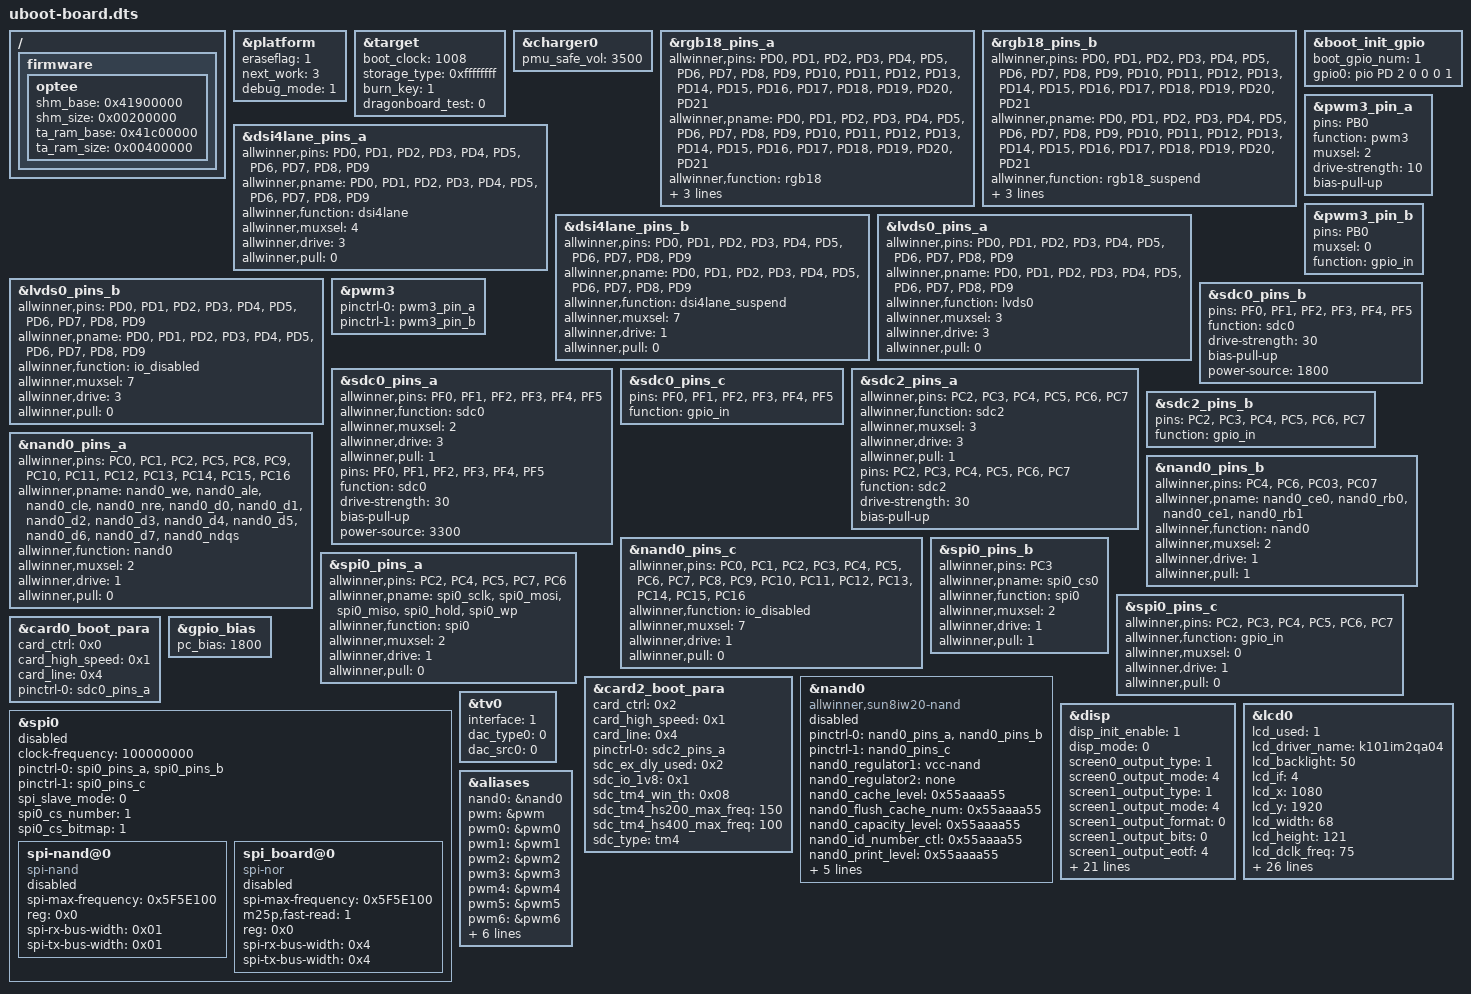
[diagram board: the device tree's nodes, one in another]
/*
 * Allwinner Technology CO., Ltd. sun8iw20p1 soc board.
 *
 * soc board support.
 */
//  #include "ebyte-t113-mipi.dtsi"
/{
	firmware {
		optee {
			shm_base = <0x41900000>;
			shm_size = <0x00200000>;
			ta_ram_base = <0x41c00000>;
			ta_ram_size = <0x00400000>;
		};
	};
};

&platform {
	eraseflag   = <1>;
	next_work   = <3>;
	debug_mode  = <1>;
};

&target {
	boot_clock = <1008>;	/*CPU boot frequency, Unit: MHz*/
	storage_type = <0xffffffff>; /*boot medium, 0-nand, 1-card0, 2-card2, -1(defualt)auto scan*/
	burn_key = <1>;		/*1:support burn key; 0:not support burn key*/
	dragonboard_test = <0>;	/*1:support card boot dragonboard; 0:not support card boot dragonboard*/
};


&charger0 {
	pmu_safe_vol = <3500>;
};

&rgb18_pins_a {
	allwinner,pins = "PD0", "PD1", "PD2", "PD3", "PD4", "PD5", "PD6", "PD7", "PD8", "PD9", \
	"PD10", "PD11", "PD12", "PD13", "PD14", "PD15", "PD16", "PD17", "PD18", "PD19", \
	"PD20", "PD21";
	allwinner,pname = "PD0", "PD1", "PD2", "PD3", "PD4", "PD5", "PD6", "PD7", "PD8", "PD9", \
	"PD10", "PD11", "PD12", "PD13", "PD14", "PD15", "PD16", "PD17", "PD18", "PD19", \
	"PD20", "PD21";
	allwinner,function = "rgb18";
	allwinner,muxsel = <2>;
	allwinner,drive = <3>;
	allwinner,pull = <0>;
};

&rgb18_pins_b {
	allwinner,pins = "PD0", "PD1", "PD2", "PD3", "PD4", "PD5", "PD6", "PD7", "PD8", "PD9", \
	"PD10", "PD11", "PD12", "PD13", "PD14", "PD15", "PD16", "PD17", "PD18", "PD19", \
	"PD20", "PD21";
	allwinner,pname = "PD0", "PD1", "PD2", "PD3", "PD4", "PD5", "PD6", "PD7", "PD8", "PD9", \
	"PD10", "PD11", "PD12", "PD13", "PD14", "PD15", "PD16", "PD17", "PD18", "PD19", \
	"PD20", "PD21";
	allwinner,function = "rgb18_suspend";
	allwinner,muxsel = <7>;
	allwinner,drive = <1>;
	allwinner,pull = <0>;
};

&dsi4lane_pins_a {
    allwinner,pins = "PD0", "PD1", "PD2", "PD3", "PD4", "PD5", "PD6", "PD7", "PD8", "PD9";
    allwinner,pname = "PD0", "PD1", "PD2", "PD3", "PD4", "PD5", "PD6", "PD7", "PD8", "PD9";
    allwinner,function = "dsi4lane";
    allwinner,muxsel = <4>;
    allwinner,drive = <3>;
    allwinner,pull = <0>;
	};

&dsi4lane_pins_b {
    allwinner,pins = "PD0", "PD1", "PD2", "PD3", "PD4", "PD5", "PD6", "PD7", "PD8", "PD9";
    allwinner,pname = "PD0", "PD1", "PD2", "PD3", "PD4", "PD5", "PD6", "PD7", "PD8", "PD9";
    allwinner,function = "dsi4lane_suspend";
    allwinner,muxsel = <7>;
    allwinner,drive = <1>;
    allwinner,pull = <0>;
};

&lvds0_pins_a {
	allwinner,pins  = "PD0", "PD1", "PD2", "PD3", "PD4", "PD5", "PD6", "PD7", "PD8", "PD9";
	allwinner,pname = "PD0", "PD1", "PD2", "PD3", "PD4", "PD5", "PD6", "PD7", "PD8", "PD9";
	allwinner,function = "lvds0";
	allwinner,muxsel = <3>;
	allwinner,drive = <3>;
	allwinner,pull = <0>;
};

&lvds0_pins_b {
	allwinner,pins  = "PD0", "PD1", "PD2", "PD3", "PD4", "PD5", "PD6", "PD7", "PD8", "PD9";
	allwinner,pname = "PD0", "PD1", "PD2", "PD3", "PD4", "PD5", "PD6", "PD7", "PD8", "PD9";
	allwinner,function = "io_disabled";
	allwinner,muxsel = <7>;
	allwinner,drive = <3>;
	allwinner,pull = <0>;
};


&boot_init_gpio{
	boot_gpio_num=<1>;
	gpio0        = <&pio PD 2 0 0 0 1>;
    status = "okay";
};


&pwm3_pin_a {
	pins = "PB0";
	function = "pwm3";
	muxsel = <2>;
	drive-strength = <10>;
	bias-pull-up;
};

&pwm3_pin_b {
	pins = "PB0";
	muxsel = <0>;
	function = "gpio_in";
};

&pwm3 {
	pinctrl-names = "active", "sleep";
	pinctrl-0 = <&pwm3_pin_a>;
	pinctrl-1 = <&pwm3_pin_b>;
	status = "okay";
};

&sdc0_pins_a {
	allwinner,pins = "PF0", "PF1", "PF2",
			 "PF3", "PF4", "PF5";
	allwinner,function = "sdc0";
	allwinner,muxsel = <2>;
	allwinner,drive = <3>;
	allwinner,pull = <1>;
	pins = "PF0", "PF1", "PF2",
	       "PF3", "PF4", "PF5";
	function = "sdc0";
	drive-strength = <30>;
	bias-pull-up;
	power-source = <3300>;
};

&sdc0_pins_b {
	pins = "PF0", "PF1", "PF2",
	       "PF3", "PF4", "PF5";
	function = "sdc0";
	drive-strength = <30>;
	bias-pull-up;
	power-source = <1800>;
};

&sdc0_pins_c {
		pins = "PF0", "PF1", "PF2",
			"PF3", "PF4", "PF5";
		function = "gpio_in";

};


&sdc2_pins_a {
	allwinner,pins = "PC2", "PC3", "PC4",
			 "PC5", "PC6", "PC7";
	allwinner,function = "sdc2";
	allwinner,muxsel = <3>;
	allwinner,drive = <3>;
	allwinner,pull = <1>;
	pins = "PC2", "PC3", "PC4",
		"PC5", "PC6", "PC7";
	function = "sdc2";
	drive-strength = <30>;
	bias-pull-up;

};

&sdc2_pins_b {
	pins = "PC2", "PC3", "PC4",
	       "PC5", "PC6", "PC7";
	function = "gpio_in";
};



&nand0_pins_a {
	allwinner,pins = "PC0", "PC1", "PC2", "PC5",
			 "PC8", "PC9", "PC10", "PC11",
			 "PC12", "PC13", "PC14", "PC15",
			 "PC16";
	allwinner,pname= "nand0_we", "nand0_ale","nand0_cle", "nand0_nre",
			 "nand0_d0", "nand0_d1", "nand0_d2", "nand0_d3",
			 "nand0_d4", "nand0_d5", "nand0_d6", "nand0_d7",
			 "nand0_ndqs";
	allwinner,function = "nand0";
	allwinner,muxsel = <2>;
	allwinner,drive = <1>;
	allwinner,pull = <0>;
};

&nand0_pins_b {
	allwinner,pins = "PC4", "PC6", "PC03", "PC07";
	allwinner,pname= "nand0_ce0", "nand0_rb0", "nand0_ce1", "nand0_rb1";
	allwinner,function = "nand0";
	allwinner,muxsel = <2>;
	allwinner,drive = <1>;
	allwinner,pull = <1>;	/* only RB&CE should be pulled up */
};

&nand0_pins_c {
	allwinner,pins = "PC0", "PC1", "PC2", "PC3",
			 "PC4", "PC5", "PC6", "PC7",
			 "PC8", "PC9", "PC10", "PC11",
			 "PC12", "PC13", "PC14", "PC15",
			 "PC16";
	allwinner,function = "io_disabled";
	allwinner,muxsel = <7>;
	allwinner,drive = <1>;
	allwinner,pull = <0>;
};

&spi0_pins_a {
	allwinner,pins = "PC2", "PC4", "PC5",
			"PC7", "PC6";
	allwinner,pname = "spi0_sclk", "spi0_mosi",
			"spi0_miso", "spi0_hold", "spi0_wp";
	allwinner,function = "spi0";
	allwinner,muxsel = <2>;
	allwinner,drive = <1>;
	allwinner,pull = <0>;
};

&spi0_pins_b {
	allwinner,pins = "PC3";
	allwinner,pname = "spi0_cs0";
	allwinner,function = "spi0";
	allwinner,muxsel = <2>;
	allwinner,drive = <1>;
	allwinner,pull = <1>;   // only CS should be pulled up
};

&spi0_pins_c {
	allwinner,pins = "PC2", "PC3", "PC4", "PC5",
			"PC6", "PC7";
	allwinner,function = "gpio_in";
	allwinner,muxsel = <0>;
	allwinner,drive = <1>;
	allwinner,pull = <0>;
};

&card0_boot_para {  /* Avoid dtc compiling warnings. @TODO: Developer should modify this to the actual value */
	/* reg = <0x0 0x2 0x0 0x0>;  [> Avoid dtc compiling warnings. @TODO: Developer should modify this to the actual value <] */
	device_type = "card0_boot_para";
	card_ctrl = <0x0>;
	card_high_speed = <0x1>;
	card_line = <0x4>;
	pinctrl-0 = <&sdc0_pins_a>;
};

&card2_boot_para {  /* Avoid dtc compiling warnings. @TODO: Developer should modify this to the actual value */
	/* reg = <0x0 0x3 0x0 0x0>;  [> Avoid dtc compiling warnings. @TODO: Developer should modify this to the actual value <] */
	device_type = "card2_boot_para";
	card_ctrl = <0x2>;
	card_high_speed = <0x1>;
	card_line = <0x4>;
	pinctrl-0 = <&sdc2_pins_a>;
	sdc_ex_dly_used = <0x2>;
	sdc_io_1v8 = <0x1>;
	sdc_tm4_win_th = <0x08>;
	sdc_tm4_hs200_max_freq = <150>;
	sdc_tm4_hs400_max_freq = <100>;
	sdc_type = "tm4";
};
&gpio_bias {  /* Avoid dtc compiling warnings. @TODO: Developer should modify this to the actual value */
	device_type = "gpio_bias";
	pc_bias = <1800>;
};

&nand0 {
	compatible = "allwinner,sun8iw20-nand";
	device_type = "nand0";
	//reg = <0x0 0x04011000 0x0 0x1000>;/* nand0 */
	pinctrl-names = "default", "sleep";
	pinctrl-0 = <&nand0_pins_a &nand0_pins_b>;
	pinctrl-1 = <&nand0_pins_c>;
	nand0_regulator1 = "vcc-nand";
	nand0_regulator2 = "none";
	nand0_cache_level = <0x55aaaa55>;
	nand0_flush_cache_num = <0x55aaaa55>;
	nand0_capacity_level = <0x55aaaa55>;
	nand0_id_number_ctl = <0x55aaaa55>;
	nand0_print_level = <0x55aaaa55>;
	nand0_p0 = <0x55aaaa55>;
	nand0_p1 = <0x55aaaa55>;
	nand0_p2 = <0x55aaaa55>;
	nand0_p3 = <0x55aaaa55>;
	chip_code = "sun8iw20";
	status = "disabled";
};

&spi0 {
	clock-frequency = <100000000>;
	pinctrl-0 = <&spi0_pins_a &spi0_pins_b>;
	pinctrl-1 = <&spi0_pins_c>;
	pinctrl-names = "default", "sleep";
	/*spi-supply = <&reg_dcdc1>;*/
	spi_slave_mode = <0>;
	spi0_cs_number = <1>;
	spi0_cs_bitmap = <1>;
	status = "disabled";

	spi-nand@0 {
		compatible = "spi-nand";
		spi-max-frequency=<0x5F5E100>;
		reg = <0x0>;
		spi-rx-bus-width=<0x01>;
		spi-tx-bus-width=<0x01>;
		status="disabled";
	};

	spi_board@0 {
		device_type = "spi_board0";
		compatible = "spi-nor";
		spi-max-frequency = <0x5F5E100>;
		m25p,fast-read = <1>;
		reg = <0x0>;
		spi-rx-bus-width = <0x4>;
		spi-tx-bus-width = <0x4>;
		status = "disabled";
	};
};

/*----------------------------------------------------------------------------------
disp init configuration

disp_mode             (0:screen0<screen0,fb0>)
screenx_output_type   (0:none; 1:lcd; 2:tv; 5:vdpo)
fbx format            (4:RGB655 5:RGB565 6:RGB556 7:ARGB1555 8:RGBA5551 9:RGB888 10:ARGB8888 12:ARGB4444)
fbx pixel sequence    (0:ARGB 1:BGRA 2:ABGR 3:RGBA)
fb0_scaler_mode_enable(scaler mode enable, used FE)
fbx_width,fbx_height  (framebuffer horizontal/vertical pixels, fix to output resolution while equal 0)
lcdx_backlight        (lcd init backlight,the range:[0,256],default:197
lcdx_yy               (lcd init screen bright/contrast/saturation/hue, value:0~100, default:50/50/57/50)
lcd0_contrast         (LCD contrast, 0~100)
lcd0_saturation       (LCD saturation, 0~100)
lcd0_hue              (LCD hue, 0~100)
framebuffer software rotation setting:
disp_rotation_used:   (0:disable; 1:enable,you must set fbX_width to lcd_y,
set fbX_height to lcd_x)
degreeX:              (X:screen index; 0:0 degree; 1:90 degree; 3:270 degree)
degreeX_Y:            (X:screen index; Y:layer index 0~15; 0:0 degree; 1:90 degree; 3:270 degree)
devX_output_type : config output type in bootGUI framework in UBOOT-2018.
				   (0:none; 1:lcd; 2:tv;)
devX_output_mode : config output resolution(see include/video/sunxi_display2.h) of bootGUI framework in UBOOT-2018
devX_screen_id   : config display index of bootGUI framework in UBOOT-2018
devX_do_hpd      : whether do hpd detectation or not in UBOOT-2018
chn_cfg_mode     : Hardware DE channel allocation config. 0:single display with 6
				   channel, 1:dual display with 4 channel in main display and 2 channel in second
                   display, 2:dual display with 3 channel in main display and 3 channel in second
                   in display.
----------------------------------------------------------------------------------*/
&disp {
	disp_init_enable         = <1>;
	disp_mode                = <0>;

	/*lcd*/
	screen0_output_type      = <1>;
	screen0_output_mode      = <4>;

	/*cbvs*/
	// screen0_output_type      = <2>;
	// screen0_output_mode      = <14>;


	screen1_output_type      = <1>;
	screen1_output_mode      = <4>;

	screen1_output_format    = <0>;
	screen1_output_bits      = <0>;
	screen1_output_eotf      = <4>;
	screen1_output_cs        = <257>;
	screen1_output_range     = <2>;
	screen1_output_scan      = <0>;
	screen1_output_aspect_ratio = <8>;

	/*lcd*/
	dev0_output_type         = <1>;
	dev0_output_mode         = <4>;
	dev0_screen_id           = <0>;
	dev0_do_hpd              = <0>;
	/*cbvs*/
	// dev0_output_type         = <2>;
	// dev0_output_mode         = <14>;
	// dev0_screen_id           = <0>;
	// dev0_do_hpd              = <1>;

	dev1_output_type         = <4>;
	dev1_output_mode         = <10>;
	dev1_screen_id           = <1>;
	dev1_do_hpd              = <1>;
	/*cvbs*/
	// dev1_output_type         = <1>;
	// dev1_output_mode         = <4>;
	// dev1_screen_id           = <1>;
	// dev1_do_hpd              = <1>;


	def_output_dev           = <0>;

	/*lcd*/
	fb0_format               = <0>;
	fb0_width                = <1080>;
	fb0_height               = <1920>;
	/*cvbs*/
	// fb0_format               = <0>;
	// fb0_width                = <720>;
	// fb0_height               = <480>;

	/*lcd*/
	fb1_format               = <0>;
	fb1_width                = <0>;
	fb1_height               = <0>;
	chn_cfg_mode             = <1>;
	/*cvbs*/
	// fb1_format               = <0>;
	// fb1_width                = <1920>;
	// fb1_height               = <1080>;
	// chn_cfg_mode             = <1>;

	disp_para_zone           = <1>;
	/*VCC-LCD*/
/*	dc1sw-supply = <&reg_dc1sw>;*/
	/*VCC-DSI*/
/*	eldo3-supply = <&reg_eldo3>;*/
	/*VCC-PD*/
/*	dcdc1-supply = <&reg_dcdc1>;*/
};
/*----------------------------------------------------------------------------------
;lcd0 configuration

;lcd_if:               0:hv(sync+de); 1:8080; 2:ttl; 3:lvds; 4:dsi; 5:edp; 6:extend dsi
;lcd_hv_if             0:Parallel RGB; 8:Serial RGB; 10:Dummy RGB; 11: RGB Dummy;12:CCIR656
;lcd_hv_clk_phase      0:0 degree;1:90 degree;2:180 degree;3:270 degree
;lcd_hv_sync_polarity  0:vs low,hs low; 1:vs high,hslow; 2:vs low,hs high; 3:vs high,hs high
;lcd_hv_syuv_seq       0:YUYV; 1:YVYU; 2:UYVY; 3:VYUY
;lcd_cpu_if            0:18bit/1 cycle parallel(RGB666); 4:16bit/1cycle parallel (RGB565)
;                      6:18bit/3 cycle parallel(RGB666); 7:16bit/2cycle parallel (RGB565)
;lcd_cpu_te            0:frame auto trigger; 1:frame triggered by te rising edge; 2:frame triggered by te falling edge;
;lcd_dsi_if            0:video mode; 1: Command mode; 2:video burst mode
;lcd_dsi_te            0:frame auto trigger; 1:frame triggered by te rising edge; 2:frame triggered by te falling edge;
;lcd_x:                lcd horizontal resolution
;lcd_y:                lcd vertical resolution
;lcd_width:            width of lcd in mm
;lcd_height:           height of lcd in mm
;lcd_dclk_freq:        in MHZ unit
;lcd_pwm_freq:         in HZ unit
;lcd_pwm_pol:          lcd backlight PWM polarity
;lcd_pwm_max_limit     lcd backlight PWM max limit(<=255)
;lcd_hbp:              hsync back porch(pixel) + hsync plus width(pixel);
;lcd_ht:               hsync total cycle(pixel)
;lcd_vbp:              vsync back porch(line) + vysnc plus width(line)
;lcd_vt:               vysnc total cycle(line)
;lcd_hspw:             hsync plus width(pixel)
;lcd_vspw:             vysnc plus width(pixel)
;lcd_lvds_if:          0:single link;  1:dual link
;lcd_lvds_colordepth:  0:8bit; 1:6bit
;lcd_lvds_mode:        0:NS mode; 1:JEIDA mode
;lcd_frm:              0:disable; 1:enable rgb666 dither; 2:enable rgb656 dither
;lcd_io_phase:         0:noraml; 1:intert phase(0~3bit: vsync phase; 4~7bit:hsync phase;
;                      8~11bit:dclk phase; 12~15bit:de phase)
;lcd_gamma_en          lcd gamma correction enable
;lcd_bright_curve_en   lcd bright curve correction enable
;lcd_cmap_en           lcd color map function enable
;deu_mode              0:smoll lcd screen; 1:large lcd screen(larger than 10inch)
;lcdgamma4iep:         Smart Backlight parameter, lcd gamma vale * 10;
;                      decrease it while lcd is not bright enough; increase while lcd is too bright
;smart_color           90:normal lcd screen 65:retina lcd screen(9.7inch)
;Pin setting for special function ie.LVDS, RGB data or vsync
;   name(donot care) = port:PD12<pin function><pull up or pull down><drive ability><output level>
;Pin setting for gpio:
;   lcd_gpio_X     = port:PD12<pin function><pull up or pull down><drive ability><output level>
;Pin setting for backlight enable pin
;   lcd_bl_en     = port:PD12<pin function><pull up or pull down><drive ability><output level>
;fsync setting, pulse to csi
;lcd_fsync_en          (0:disable fsync,1:enable)
;lcd_fsync_act_time    (active time of fsync, unit:pixel)
;lcd_fsync_dis_time    (disactive time of fsync, unit:pixel)
;lcd_fsync_pol         (0:positive;1:negative)
;gpio config: <&pio for cpu or &r_pio for cpus, port, port num, pio function,
pull up or pull down(default 0), driver level(default 1), data>
;For dual link lvds: use lvds2link_pins_a  and lvds2link_pins_b instead
;For rgb24: use rgb24_pins_a  and rgb24_pins_b instead
;For lvds1: use lvds1_pins_a  and lvds1_pins_b instead
;For lvds0: use lvds0_pins_a  and lvds0_pins_b instead
;----------------------------------------------------------------------------------*/
// panel-lt8912b-hdmi  k101im2qa04 he0801a068 jd9366ab_3 jd9161z
&lcd0 {
	lcd_used            = <1>;
	lcd_driver_name     = "k101im2qa04";
    lcd_backlight       = <50>;

	lcd_if              = <4>;

	lcd_x               = <1080>;
	lcd_y               = <1920>;
	lcd_width           = <68>;
	lcd_height          = <121>;
	lcd_dclk_freq       = <75>;
	
	lcd_pwm_used        = <1>;
	lcd_pwm_ch          = <2>;
	lcd_pwm_freq        = <25000>;
	lcd_pwm_pol         = <1>;
	lcd_pwm_max_limit   = <255>;

	/*atk*/
	lcd_hbp             = <52>;
	lcd_ht              = <1188>;
	lcd_hspw            = <8>;
	lcd_vbp             = <15>;
	lcd_vt              = <1957>;
	lcd_vspw            = <6>;

	/*ebyte*/
	// lcd_hbp             = <52>;
	// lcd_ht              = <828>;
	// lcd_hspw            = <8>;
	// lcd_vbp             = <15>;
	// lcd_vt              = <1317>;
	// lcd_vspw            = <6>;


	lcd_dsi_lane        = <4>;
	lcd_dsi_if          = <0>;
	lcd_dsi_format      = <0>;
	lcd_dsi_te          = <0>;
	lcd_frm             = <0>;
	lcd_io_phase        = <0>;
	lcd_gamma_en        = <0>;
	lcd_bright_curve_en = <0>;
	lcd_cmap_en         = <0>;

	deu_mode            = <0>;
	lcdgamma4iep        = <22>;
	smart_color         = <90>;

	lcd_gpio_0 = <&pio PD 19 GPIO_ACTIVE_HIGH>;
	pinctrl-0 = <&dsi4lane_pins_a>;
	pinctrl-1 = <&dsi4lane_pins_b>;
};

&tv0 {
	interface       = <1>;
	dac_type0       = <0>;
	dac_src0        = <0>;

	status =  "okay";
};


&aliases {
	nand0 = &nand0;
	pwm = &pwm;
	pwm0 = &pwm0;
	pwm1 = &pwm1;
	pwm2 = &pwm2;
	pwm3 = &pwm3;
	pwm4 = &pwm4;
	pwm5 = &pwm5;
	pwm6 = &pwm6;
	pwm7 = &pwm7;
	disp = &disp;
	lcd0 = &lcd0;
	lcd1 = &lcd1;
	eink = &eink;
	spi0 = &spi0;

};
